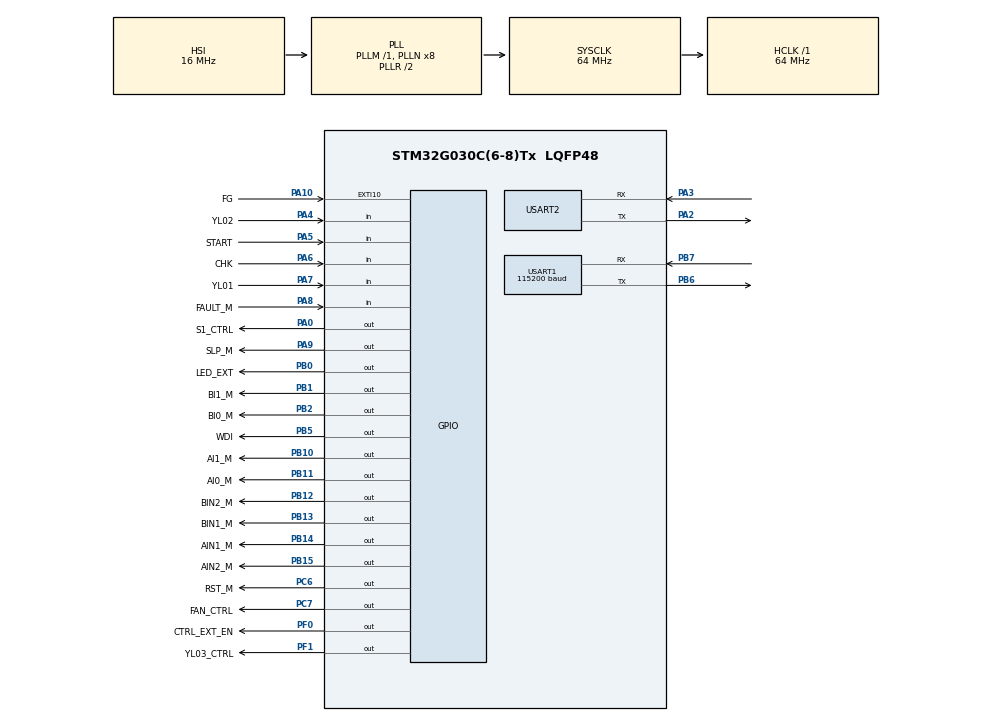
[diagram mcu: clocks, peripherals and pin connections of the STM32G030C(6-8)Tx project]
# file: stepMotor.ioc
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Mcu.Family=STM32G0
Mcu.Name=STM32G030C(6-8)Tx
Mcu.Package=LQFP48
NVIC.EXTI4_15_IRQn=true\:0\:0\:false\:false\:true\:true\:true\:true
NVIC.TIM14_IRQn=true\:0\:0\:false\:false\:true\:true\:true\:true
NVIC.USART1_IRQn=true\:0\:0\:false\:false\:true\:true\:true\:true
NVIC.USART2_IRQn=true\:0\:0\:false\:false\:true\:true\:true\:true
PA0.GPIO_Label=S1_CTRL
PA0.Signal=GPIO_Output
PA10.GPIO_Label=FG
PA10.GPIO_PuPd=GPIO_PULLDOWN
PA10.Signal=GPXTI10
PA13.Mode=Serial_Wire
PA13.Signal=SYS_SWDIO
PA14-BOOT0.Mode=Serial_Wire
PA14-BOOT0.Signal=SYS_SWCLK
PA2.Mode=Asynchronous
PA2.Signal=USART2_TX
PA3.Mode=Asynchronous
PA3.Signal=USART2_RX
PA4.GPIO_Label=YL02
PA4.Signal=GPIO_Input
PA5.GPIO_Label=START
PA5.Signal=GPIO_Input
PA6.GPIO_Label=CHK
PA6.Signal=GPIO_Input
PA7.GPIO_Label=YL01
PA7.Signal=GPIO_Input
PA8.GPIO_Label=FAULT_M
PA8.Signal=GPIO_Input
PA9.GPIO_Label=SLP_M
PA9.Signal=GPIO_Output
PB0.GPIO_Label=LED_EXT
PB0.Signal=GPIO_Output
PB1.GPIO_Label=BI1_M
PB1.Signal=GPIO_Output
PB10.GPIO_Label=AI1_M
PB10.Signal=GPIO_Output
PB11.GPIO_Label=AI0_M
PB11.Signal=GPIO_Output
PB12.GPIO_Label=BIN2_M
PB12.Signal=GPIO_Output
PB13.GPIO_Label=BIN1_M
PB13.Signal=GPIO_Output
PB14.GPIO_Label=AIN1_M
PB14.Signal=GPIO_Output
PB15.GPIO_Label=AIN2_M
PB15.Signal=GPIO_Output
PB2.GPIO_Label=BI0_M
PB2.Signal=GPIO_Output
PB5.GPIO_Label=WDI
PB5.Signal=GPIO_Output
PB6.Mode=Asynchronous
PB6.Signal=USART1_TX
PB7.Mode=Asynchronous
PB7.Signal=USART1_RX
PC6.GPIO_Label=RST_M
PC6.GPIO_PuPd=GPIO_PULLUP
PC6.Signal=GPIO_Output
PC7.GPIO_Label=FAN_CTRL
PC7.Signal=GPIO_Output
PF0-OSC_IN\ (PF0).GPIO_Label=CTRL_EXT_EN
PF0-OSC_IN\ (PF0).Signal=GPIO_Output
PF1-OSC_OUT\ (PF1).GPIO_Label=YL03_CTRL
PF1-OSC_OUT\ (PF1).Signal=GPIO_Output
ProjectManager.HeapSize=0x200
ProjectManager.StackSize=0x400
ProjectManager.TargetToolchain=MDK-ARM V5.32
RCC.ADCFreq_Value=64000000
RCC.AHBFreq_Value=64000000
RCC.CortexFreq_Value=64000000
RCC.EXTERNAL_CLOCK_VALUE=12288000
RCC.HCLKFreq_Value=64000000
RCC.HSE_VALUE=8000000
RCC.HSI_VALUE=16000000
RCC.LSE_VALUE=32768
RCC.SYSCLKFreq_VALUE=64000000
RCC.SYSCLKSource=RCC_SYSCLKSOURCE_PLLCLK
RCC.VCOOutputFreq_Value=128000000
TIM14.ClockDivision=TIM_CLOCKDIVISION_DIV1
TIM14.Period=356
TIM14.Prescaler=63
USART1.BaudRate=115200
USART1.VirtualMode-Asynchronous=VM_ASYNC
USART2.VirtualMode-Asynchronous=VM_ASYNC
VP_TIM14_VS_ClockSourceINT.Mode=Enable_Timer
board=custom

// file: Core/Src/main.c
/* USER CODE BEGIN Header */
/**
  ******************************************************************************
  * @file           : main.c
  * @brief          : Main program body
  ******************************************************************************
  * @attention
  *
  * Copyright (c) 2023 STMicroelectronics.
  * All rights reserved.
  *
  * This software is licensed under terms that can be found in the LICENSE file
  * in the root directory of this software component.
  * If no LICENSE file comes with this software, it is provided AS-IS.
  *
  ******************************************************************************
  */
/* USER CODE END Header */
#include "main.h"
#include "tim.h"
#include "usart.h"
#include "gpio.h"

/* USER CODE BEGIN Includes */
#include "./Scheduler/Sch.h"
/* USER CODE END Includes */

void SystemClock_Config(void);

int main(void)
{

  /* MCU Configuration--------------------------------------------------------*/

  /* Reset of all peripherals, Initializes the Flash interface and the Systick. */
  HAL_Init();

  /* Configure the system clock */
  SystemClock_Config();

  /* Initialize all configured peripherals */
  MX_GPIO_Init();
  MX_TIM14_Init();
  MX_USART1_UART_Init();
  MX_USART2_UART_Init();
  /* USER CODE BEGIN 2 */
  SCH_Init();
  SCH_Start();
  /* USER CODE END 2 */

  /* Infinite loop */
  /* USER CODE BEGIN WHILE */
  while (1)
  {   SCH_Dispatch_Tasks();
    /* USER CODE END WHILE */

  }
}

void SystemClock_Config(void)
{
  RCC_OscInitTypeDef RCC_OscInitStruct = {0};
  RCC_ClkInitTypeDef RCC_ClkInitStruct = {0};

  /** Configure the main internal regulator output voltage
  */
  HAL_PWREx_ControlVoltageScaling(PWR_REGULATOR_VOLTAGE_SCALE1);

  /** Initializes the RCC Oscillators according to the specified parameters
  * in the RCC_OscInitTypeDef structure.
  */
  RCC_OscInitStruct.OscillatorType = RCC_OSCILLATORTYPE_HSI;
  RCC_OscInitStruct.HSIState = RCC_HSI_ON;
  RCC_OscInitStruct.HSIDiv = RCC_HSI_DIV1;
  RCC_OscInitStruct.HSICalibrationValue = RCC_HSICALIBRATION_DEFAULT;
  RCC_OscInitStruct.PLL.PLLState = RCC_PLL_ON;
  RCC_OscInitStruct.PLL.PLLSource = RCC_PLLSOURCE_HSI;
  RCC_OscInitStruct.PLL.PLLM = RCC_PLLM_DIV1;
  RCC_OscInitStruct.PLL.PLLN = 8;
  RCC_OscInitStruct.PLL.PLLP = RCC_PLLP_DIV2;
  RCC_OscInitStruct.PLL.PLLR = RCC_PLLR_DIV2;
  if (HAL_RCC_OscConfig(&RCC_OscInitStruct) != HAL_OK)
  {
    Error_Handler();
  }

  /** Initializes the CPU, AHB and APB buses clocks
  */
  RCC_ClkInitStruct.ClockType = RCC_CLOCKTYPE_HCLK|RCC_CLOCKTYPE_SYSCLK
                              |RCC_CLOCKTYPE_PCLK1;
  RCC_ClkInitStruct.SYSCLKSource = RCC_SYSCLKSOURCE_PLLCLK;
  RCC_ClkInitStruct.AHBCLKDivider = RCC_SYSCLK_DIV1;
  RCC_ClkInitStruct.APB1CLKDivider = RCC_HCLK_DIV1;

  if (HAL_RCC_ClockConfig(&RCC_ClkInitStruct, FLASH_LATENCY_2) != HAL_OK)
  {
    Error_Handler();
  }
}

void Error_Handler(void)
{
  /* USER CODE BEGIN Error_Handler_Debug */
  /* User can add his own implementation to report the HAL error return state */
  __disable_irq();
  while (1)
  {
      HAL_Delay(100);
      // Toggle_SYSTEM_OK();
  }
  /* USER CODE END Error_Handler_Debug */
}
